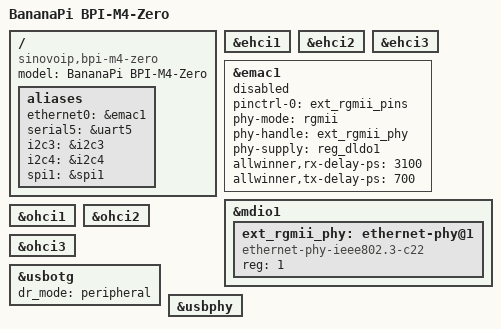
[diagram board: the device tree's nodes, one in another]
// SPDX-License-Identifier: (GPL-2.0+ OR MIT)
/*
 * Copyright (c) 2024 Patrick Yavitz <pyavitz@armbian.com>
 */

/dts-v1/;

#include "sun50i-h618-bananapi-m4.dtsi"

/ {
	model = "BananaPi BPI-M4-Zero";
	compatible = "sinovoip,bpi-m4-zero", "allwinner,sun50i-h618";

	aliases {
		ethernet0 = &emac1;
		serial5 = &uart5;
		i2c3 = &i2c3;
		i2c4 = &i2c4;
		spi1 = &spi1;
	};
};

/* Connected to an on-board RTL8821CU USB WiFi chip. */
&ehci1 {
	status = "okay";
};

&ehci2 {
	status = "okay";
};

&ehci3 {
	status = "okay";
};

&emac1 {
	status = "disabled";
	pinctrl-0 = <&ext_rgmii_pins>;
	pinctrl-names = "default";
	phy-mode = "rgmii";
	phy-handle = <&ext_rgmii_phy>;
	phy-supply = <&reg_dldo1>;
	allwinner,rx-delay-ps = <3100>;
	allwinner,tx-delay-ps = <700>;
};

&mdio1 {
	ext_rgmii_phy: ethernet-phy@1 {
		compatible = "ethernet-phy-ieee802.3-c22";
		reg = <1>;
	};
};

&ohci1 {
	status = "okay";
};

&ohci2 {
	status = "okay";
};

&ohci3 {
	status = "okay";
};

&usbotg {
	status = "okay";
	dr_mode = "peripheral";
};

&usbphy {
	status = "okay";
};
